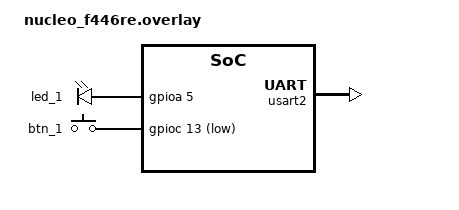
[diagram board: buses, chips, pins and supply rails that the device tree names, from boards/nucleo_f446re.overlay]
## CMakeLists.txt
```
cmake_minimum_required(VERSION 3.20.0)

find_package(Zephyr REQUIRED HINTS $ENV{ZEPHYR_BASE})
project(device_tree)

target_sources(app PRIVATE src/main.c)
```

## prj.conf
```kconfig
CONFIG_USB_DEVICE_STACK=y
CONFIG_USB_DEVICE_INITIALIZE_AT_BOOT=y
CONFIG_USB_CDC_ACM=y

CONFIG_SERIAL=y
CONFIG_CONSOLE=y
CONFIG_UART_CONSOLE=y
CONFIG_UART_INTERRUPT_DRIVEN=y
```

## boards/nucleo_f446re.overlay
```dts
/{
  aliases {
    my-button=&btn_1;
    my-led=&led_1;
  };
  chosen {
    zephyr,console=&usart2;
  };


  leds: leds{
     compatible="gpio-leds";
     led_1: green_led{
        gpios=<&gpioa 5 GPIO_ACTIVE_HIGH>;
     };
  };
  buttons:buttons{
     compatible="gpio-keys";
     btn_1:btn_1{
        gpios=<&gpioc 13 GPIO_ACTIVE_LOW>;
     };
  };

};
&usart2 {
    status="okay";
};
&usbotg_fs {
    pinctrl-0=<&usb_otg_fs_dm_pa11 &usb_otg_fs_dp_pa12>;
    pinctrl-names="default";
    status="disabled";
}; 
```

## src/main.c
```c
#include <stdio.h>
#include <zephyr/kernel.h>
#include <zephyr/drivers/gpio.h>

static const int32_t sleep_time_ms=1000;
static const struct gpio_dt_spec btn=GPIO_DT_SPEC_GET(DT_ALIAS(my_button),gpios);
static const struct gpio_dt_spec led=GPIO_DT_SPEC_GET(DT_ALIAS(my_led),gpios);

int main(){
	int res;
	int state;
	if(!gpio_is_ready_dt(&btn)){
		printk("Error in loading the pin : ");
		return 0;
	}
	res=gpio_pin_configure_dt(&btn,GPIO_INPUT);
	if(res<0){
		return 0;	
	}
	res=gpio_pin_configure_dt(&led,GPIO_OUTPUT_ACTIVE);
	printk("Button spec flags : 0x%x",btn.dt_flags);
	while(1){
		state=gpio_pin_get_dt(&btn);

		gpio_pin_set_dt(&led,state);
		if(state<0){
		  printk("Error %d : failed to read the button pin ",state);

		}else{
		  printk("Button state : %d\n",state);
		}

		k_msleep(sleep_time_ms);
	  
	}
	return 0;
  

}
```
